# tmr_revc register map
Registers are read-write, no defined reset value unless marked. A register's access mark holds for its fields unless they carry their own. Offsets are from the block's base; lines under a group give offsets from that group; [hi:lo] are bit positions; {n}, {i} and the like mark numbered series; 'fields as' and 'values as' point back to an identical list; <NAME> marks a mode.

## Memory map
0x40010000 TMR0 size 0x1000 — Low-Power Configurable Timer

## Interrupts
1 TMR (TMR0)

## TMR0 — Low-Power Configurable Timer
Base 0x40010000
0x00 CNT — Timer Counter Register.
  [31:0] COUNT — The current count value for the timer. This field increments as the timer counts.
0x04 CMP — Timer Compare Register.
  [31:0] COMPARE — The value in this register is used as the compare value for the timer's count value. The compare field meaning is determined by the specific mode of the timer.
0x08 PWM — Timer PWM Register.
  [31:0] PWM — Timer PWM Match: In PWM Mode, this field sets the count value for the first transition period of the PWM cycle. At the end of the cycle where CNT equals PWM, the PWM output transitions to the second period of the PWM cycle. The second PWM period count is stored in the CMP register. The value set for PWM must me less than the value set in CMP for PWM mode operation. Timer Capture Value: In Capture, Compare, and Capture/Compare modes, this field is used to store the CNT value when a Capture, Compare, or Capture/Compare event occurs.
0x0C INTR — Timer Interrupt Status Register.
  [0] IRQ — Interrupt Flag for Timer A.
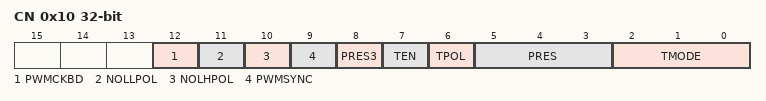
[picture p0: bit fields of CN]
0x10 CN — Timer Control Register.
  [12] PWMCKBD — PWM Phase A-Prime Output Disable
  [11] NOLLPOL — PWM Phase A-prime (Non-Overlapping Low) Polarity
  [10] NOLHPOL — PWM Phase A (Non-Overlapping High) Polarity
  [9] PWMSYNC — PWM Synchronization Mode
  [8] PRES3 — Timer Prescale Select MSB
  [7] TEN — Timer Enable
  [6] TPOL — Timer Polarity
  [5:3] PRES — Timer Prescaler Select
    0=DIV_BY_1 (Prescaler Divide-By-1); 1=DIV_BY_2 (Prescaler Divide-By-2); 2=DIV_BY_4 (Prescaler Divide-By-4); 3=DIV_BY_8 (Prescaler Divide-By-8); 4=DIV_BY_16 (Prescaler Divide-By-16); 5=DIV_BY_32 (Prescaler Divide-By-32); 6=DIV_BY_64 (Prescaler Divide-By-64); 7=DIV_BY_128 (Prescaler Divide-By-128); 0=DIV_BY_256 (Prescaler Divide-By-256); 1=DIV_BY_512 (Prescaler Divide-By-512); 2=DIV_BY_1024 (Prescaler Divide-By-1024); 3=DIV_BY_2048 (Prescaler Divide-By-2048); 4=DIV_BY_4096 (Prescaler Divide-By-4096); 5=DIV_BY_8192 (Prescaler Divide-By-8192)
  [2:0] TMODE — Mode Select
    0=ONE_SHOT (One-Shot Mode); 1=CONTINUOUS (Continuous Mode); 2=COUNTER (Counter Mode); 3=PWM (PWM Mode); 4=CAPTURE (Capture Mode); 5=COMPARE (Compare Mode); 6=GATED (Gated Mode); 7=CAPCOMP (Capture/Compare Mode)
